# ATSAMPLE1 register map
Vendor: Sample Semiconductor; File version: 1.0
Sample device for the converter tests
Registers are 32-bit, read-write, reset 0x0 unless marked. A register's access mark holds for its fields unless they carry their own. Offsets are from the block's base; lines under a group give offsets from that group; [hi:lo] are bit positions; {n}, {i} and the like mark numbered series; 'fields as' and 'values as' point back to an identical list; <NAME> marks a mode.

## Memory map
0x40003000 PORT — Port Module
0x40003800 SERCOM0 — Serial Communication Interface 0
0x40003C00 SERCOM1
{0x40004000+0x400*n} TC{n} (n=0..1) — Basic Timer Counter

## PORT — Port Module
Base 0x40003000
{0x0+0x80*i} GROUP[{i}] (i=0..1) group — Port Group
  0x00 DIR — Data Direction register
    [31:0] DIR — Port Data Direction
  0x20 IN ro — Data Input Value
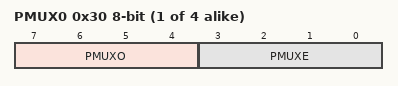
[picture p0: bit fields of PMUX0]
  {0x30+j} PMUX{j} (j=0..1) 8-bit — Peripheral Multiplexing
    [7:4] PMUXO
    [3:0] PMUXE — Peripheral Multiplexing for Even-Numbered Pin
      0=A; 1=B; 0bxxxx=ANY

## SERCOM0 — Serial Communication Interface 0
Base 0x40003800
Same registers: SERCOM1 0x40003C00
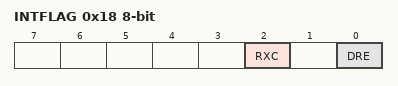
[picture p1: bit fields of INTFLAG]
0x18 INTFLAG 8-bit write-1-clears — Interrupt Flag Status and Clear
  [2] RXC, [0] DRE
0x28 DATA read-has-side-effects
0x30 DBGCTRL 8-bit wo reset 0x1 — Debug Control

## TC{n} — Basic Timer Counter
Base 0x40004000; array of 2, step 0x400
0x00 CTRLA — Control A

## Licence text in the file
Copyright (c) 2026 Sample Semiconductor. Licensed under Apache-2.0.
